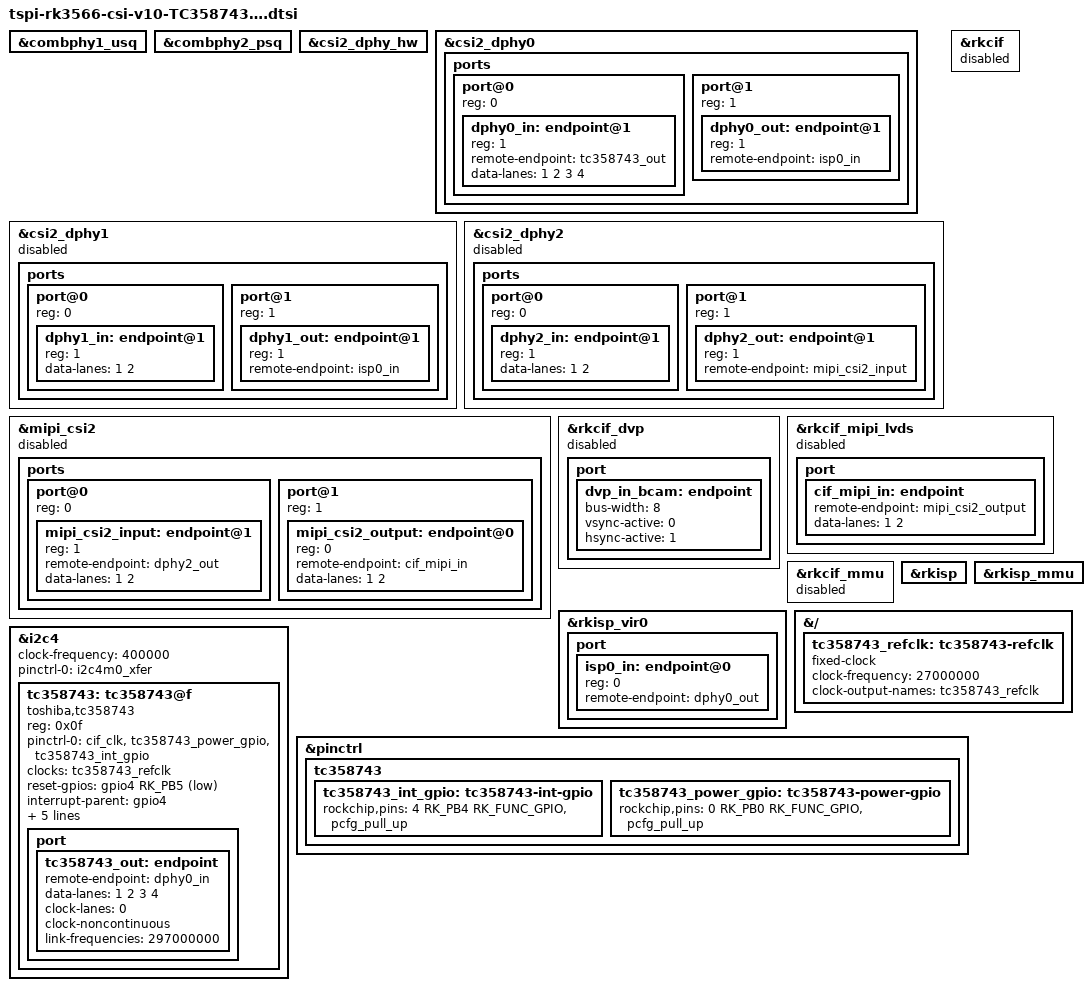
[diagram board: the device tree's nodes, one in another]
/*********************************************************************
 *           立创开发板不靠卖板赚钱，以培养中国工程师为己任  
 *         泰山派软硬件资料与相关扩展板软硬件资料官网全部开源
 *                      开发板官网：www.lckfb.com            
 *                     立创论坛：oshwhub.com/forum           
 *            关注B站：【立创开发板】，掌握我们的最新动态！  
 *********************************************************************
 * 文件名：tspi-rk3566-csi-v10
 * 描述：mipi 摄像头
 * 更新:
 * 时间          作者           联系           说明
 * 2023-09-13   吴才成    1378913492@qq.com   v1.0.0
 * 2025-12-26   风漠兮    578118086@qq.com    Fit TC358743
 *********************************************************************/

//phy u序列
&combphy1_usq {
	status = "okay";
};

//phy P序列
&combphy2_psq {
	status = "okay";
};

//dphy硬件
&csi2_dphy_hw {
	status = "okay";
};
//摄像头D-PHY接口
&csi2_dphy0 {
	status = "okay";
	/*
	 * dphy0 only used for full mode,
	 * full mode and split mode are mutually exclusive
	 */
	ports {
		#address-cells = <1>;
		#size-cells = <0>;

		port@0 {
			reg = <0>;
			#address-cells = <1>;
			#size-cells = <0>;

			dphy0_in: endpoint@1 {
				reg = <1>;
				remote-endpoint = <&tc358743_out>;
				data-lanes = <1 2 3 4>;
			};
		};

		port@1 {
			reg = <1>;
			#address-cells = <1>;
			#size-cells = <0>;

			dphy0_out: endpoint@1 {
				reg = <1>;
				remote-endpoint = <&isp0_in>;
			};
		};
	};
};

//摄像头D-PHY接口
&csi2_dphy1 {
	status = "disabled";

	/*
	 * dphy1 only used for split mode,
	 * can be used  concurrently  with dphy2
	 * full mode and split mode are mutually exclusive
	 */
	ports {
		#address-cells = <1>;
		#size-cells = <0>;

		port@0 {
			reg = <0>;
			#address-cells = <1>;
			#size-cells = <0>;

			dphy1_in: endpoint@1 {
				reg = <1>;
				//remote-endpoint = <&ov5695_out>;
				data-lanes = <1 2>;
			};
		};

		port@1 {
			reg = <1>;
			#address-cells = <1>;
			#size-cells = <0>;

			dphy1_out: endpoint@1 {
				reg = <1>;
				remote-endpoint = <&isp0_in>;
			};
		};
	};
};
//摄像头D-PHY接口
&csi2_dphy2 {
	status = "disabled";

	/*
	 * dphy2 only used for split mode,
	 * can be used  concurrently  with dphy1
	 * full mode and split mode are mutually exclusive
	 */
	ports {
		#address-cells = <1>;
		#size-cells = <0>;

		port@0 {
			reg = <0>;
			#address-cells = <1>;
			#size-cells = <0>;

			dphy2_in: endpoint@1 {
				reg = <1>;
				//remote-endpoint = <&gc5025_out>;
				data-lanes = <1 2>;
			};
		};

		port@1 {
			reg = <1>;
			#address-cells = <1>;
			#size-cells = <0>;

			dphy2_out: endpoint@1 {
				reg = <1>;
				remote-endpoint = <&mipi_csi2_input>;
			};
		};
	};
};

&mipi_csi2 {
	status = "disabled";

	ports {
		#address-cells = <1>;
		#size-cells = <0>;

		port@0 {
			reg = <0>;
			#address-cells = <1>;
			#size-cells = <0>;

			mipi_csi2_input: endpoint@1 {
				reg = <1>;
				remote-endpoint = <&dphy2_out>;
				data-lanes = <1 2>;
			};
		};

		port@1 {
			reg = <1>;
			#address-cells = <1>;
			#size-cells = <0>;

			mipi_csi2_output: endpoint@0 {
				reg = <0>;
				remote-endpoint = <&cif_mipi_in>;
				data-lanes = <1 2>;
			};
		};
	};
};

//Rockchip Camera Interface
&rkcif {
	status = "disabled";
};

//dvp接口摄像头
&rkcif_dvp {
	status = "disabled";

	port {
		/* Parallel bus endpoint */
		dvp_in_bcam: endpoint {
			// remote-endpoint = <&gc2145_out>;
			bus-width = <8>;
			vsync-active = <0>;
			hsync-active = <1>;
		};
	};
};

//LVDS接口摄像头
&rkcif_mipi_lvds {
	status = "disabled";

	port {
		cif_mipi_in: endpoint {
			remote-endpoint = <&mipi_csi2_output>;
			data-lanes = <1 2>;
		};
	};
};

//摄像头内存管理
&rkcif_mmu {
	status = "disabled";
};

//硬件图像处理器模块
&rkisp {
	status = "okay";
};

//硬件图像处理器模块内存管理器
&rkisp_mmu {
	status = "okay";
};

//图像处理接口
&rkisp_vir0 {
	status = "okay";

	port {
		#address-cells = <1>;
		#size-cells = <0>;

		isp0_in: endpoint@0 {
			reg = <0>;
			remote-endpoint = <&dphy0_out>;
		};
	};
};

&{/} {
	/* TC358743 reference clock - 27MHz from external oscillator */
	tc358743_refclk: tc358743-refclk {
		status = "okay";
		compatible = "fixed-clock";
		clock-frequency = <27000000>;
		clock-output-names = "tc358743_refclk";
		#clock-cells = <0>;
	};
};

&i2c4 {
	/* i2c4 sda conflict with camera pwdn */
	status = "okay";
	// 	//ADD///
	clock-frequency = <400000>;
	pinctrl-names = "default";
	pinctrl-0 = <&i2c4m0_xfer>;
	// /////
	tc358743: tc358743@f {
		status = "okay";
		compatible = "toshiba,tc358743";
		reg = <0x0f>;
		pinctrl-0 = <&cif_clk &tc358743_power_gpio &tc358743_int_gpio>;

		clocks = <&tc358743_refclk>;
		clock-names = "refclk";
		
        reset-gpios = <&gpio4 RK_PB5 GPIO_ACTIVE_LOW>;

		interrupt-parent = <&gpio4>;
		interrupts = <RK_PB4 IRQ_TYPE_LEVEL_LOW>;

		rockchip,camera-module-index = <0>;
		rockchip,camera-module-facing = "back";
		rockchip,camera-module-name = "tc358743-hdmi";
		rockchip,camera-module-lens-name = "hdmi-input";

		port {
			tc358743_out: endpoint {
				remote-endpoint = <&dphy0_in>;
				data-lanes = <1 2 3 4>;
				clock-lanes = <0>;
				clock-noncontinuous;
				link-frequencies = /bits/ 64 <297000000>;
			};
		};
	};
};

&pinctrl {
	tc358743 {
		tc358743_int_gpio: tc358743-int-gpio {
			rockchip,pins = <4 RK_PB4 RK_FUNC_GPIO &pcfg_pull_up>;
		};

		tc358743_power_gpio: tc358743-power-gpio {
			rockchip,pins = <0 RK_PB0 RK_FUNC_GPIO &pcfg_pull_up>;
		};
	};
};
